# prcm_scratchpad_secure register map
Vendor: Texas Instruments
Peripheral module from a debugger description file (folder CC35X1E).
Registers are 32-bit, read-write, reset 0x0 unless marked. A register's access mark holds for its fields unless they carry their own. Offsets are as the file gives them; lines under a group give offsets from that group; [hi:lo] are bit positions; {n}, {i} and the like mark numbered series; 'fields as' and 'values as' point back to an identical list; <NAME> marks a mode.

## prcm_scratchpad_secure
0x00 prcm_scpad1 — PRCM SCRATCHPAD m3 messages which should survive AON Reset and provide additional info on reset cause: Critical error types + indication if reset applied for this error- number of bits? Max number of failures for reset apply - one common value for all errors with reset apply set Counter
  [31:0] VAL — VALUE LINE 1 Scratch pad line 1
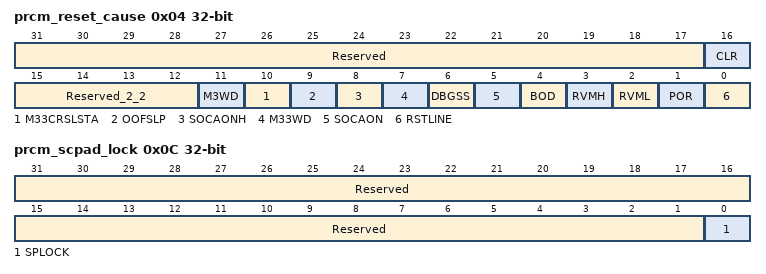
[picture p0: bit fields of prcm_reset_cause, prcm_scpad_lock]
0x04 prcm_reset_cause access per field — RESET CAUSE OSPREY PRCM AON scratch pad, this register bank is not deleted in SOC AON RESET and kept through reset/low power and brownout events
  [31:17] Reserved rw — spare
  [16] CLR wo — CLEAR write clear Reset cause clear on write - first initiate relevant source reset clear RVM - RVMTRIMCTL.RVMRSTCAUSCLR BOD - BODCTL.RSTCAUSECLR DEBUGSS - PMURSTCLR.DBGSSCAUS WDT - PMURSTCLR.WDTCAUS
  [15:12] Reserved_2_2 ro — spare
  [11] M3WD ro — M3 Watch Dog
  [10] M33CRSLSTA ro — M33 CORE SL START Core CONN STOP (M33 driven)
  [9] OOFSLP ro — OUT OF SLEEP Exit sleep on wakeup event only
  [8] SOCAONH ro — SOC AON by HOST
  [7] M33WD ro — M33 WATCH DOG
  [6] DBGSS ro — DEBUGSS REQUEST Debug req reset
  [5] SOCAON ro — SOC AON Device self reset (SOC AON by CORE )
  [4] BOD ro — BOD; applicable only when protection BOD is disabled
  [3] RVMH ro — RVM high detect of fault injection ; applicable only when protection RVMH is disabled
  [2] RVML ro — RVM low detect of fault injection ; applicable only when protection RVML is disabled
  [1] POR ro
  [0] RSTLINE ro — Reset line
0x08 prcm_scpad0 — OSPREY PRCM AON scratch pad, this register bank is not deleted in SOC AON RESET and kept through reset/low power and brownout events keep approved authenticated debug requests locked to allow OTA debug allow write only during M3 boot - M3 Privilege mode (before soc_boot_done) Allow read by M3/M33 according to configuration/firewall
  [31:0] VAL — VALUE LINE 0 Scratch pad line 0
0x0C prcm_scpad_lock — OSPREY PRCM AON scratch pad, this register bank is not deleted in SOC AON RESET and kept through reset/low power and brownout events Lock is released on power on reset allow write only during M3 boot - M3 Privilege mode (before soc_boot_done)
  [31:1] Reserved — spare
  [0] SPLOCK — SCRATCHPAD LOCK
0x1000 prcm_scpad2 — PRCM SCRATCHPAD 2 m33 messages which should survive AON Reset: OTA info -number of bits? Critical error types + indication if reset applied for this error- number of bits?
  [31:0] VAL — VALUE LINE 2 Scratch pad line 2
